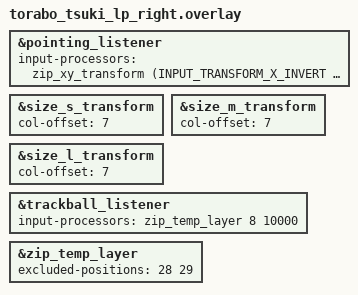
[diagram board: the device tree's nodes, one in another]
#include "torabo_tsuki_lp.dtsi"
#include <input/processors.dtsi>
#include <dt-bindings/zmk/input_transform.h>

&pointing_listener {
    input-processors = <&zip_xy_transform (INPUT_TRANSFORM_X_INVERT | INPUT_TRANSFORM_Y_INVERT)>;
};

&size_s_transform {
    col-offset = <7>;
};

&size_m_transform {
    col-offset = <7>;
};

&size_l_transform {
    col-offset = <7>;
};

&trackball_listener {
    input-processors = <&zip_temp_layer 8 10000>;
};

&zip_temp_layer {
    excluded-positions = <
        28
        29
    >;
};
